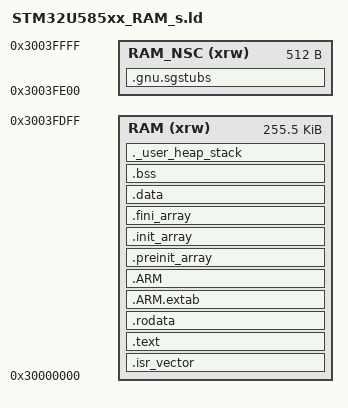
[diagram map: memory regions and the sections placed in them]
/*
******************************************************************************
**
**  File        : LinkerScript.ld (debug in RAM dedicated)
**
**  Author		: Auto-generated by STM32CubeIDE
**
**  Abstract    : Linker script for STM32U585xx Device from STM32U5 series
**                      768Kbytes RAM
**
**                Set heap size, stack size and stack location according
**                to application requirements.
**
**                Set memory bank area and size if external memory is used.
**
**  Target      : STMicroelectronics STM32
**
**  Distribution: The file is distributed as is without any warranty
**                of any kind.
**
*****************************************************************************
** @attention
**
** <h2><center>&copy; Copyright (c) 2021 STMicroelectronics.
** All rights reserved.</center></h2>
**
** This software component is licensed by ST under BSD 3-Clause license,
** the "License"; You may not use this file except in compliance with the
** License. You may obtain a copy of the License at:
**                        opensource.org/licenses/BSD-3-Clause
**
*****************************************************************************
*/

/* Entry Point */
ENTRY(Reset_Handler)

/* Highest address of the user mode stack */
_estack = ORIGIN(RAM) + LENGTH(RAM);	/* end of "RAM" Ram type memory */

_Min_Heap_Size = 0x200;	/* required amount of heap  */
_Min_Stack_Size = 0x400;	/* required amount of stack */

/* Memories definition */
MEMORY
{
  RAM	(xrw)	: ORIGIN = 0x30000000,	LENGTH = 256K - 512 /* Memory is divided. Actual start is 0x30000000 and actual length is 768K */
  RAM_NSC	(xrw)	: ORIGIN = 0x3003FE00,	LENGTH = 512    /* Non-Secure Call-able region */
}

/* Sections */
SECTIONS
{
  /* The startup code into "RAM" Ram type memory */
  .isr_vector :
  {
    . = ALIGN(8);
    KEEP(*(.isr_vector)) /* Startup code */
    . = ALIGN(8);
  } >RAM

  /* The program code and other data into "RAM" Ram type memory */
  .text :
  {
    . = ALIGN(8);
    *(.text)           /* .text sections (code) */
    *(.text*)          /* .text* sections (code) */
    *(.glue_7)         /* glue arm to thumb code */
    *(.glue_7t)        /* glue thumb to arm code */
    *(.eh_frame)

    KEEP (*(.init))
    KEEP (*(.fini))

    . = ALIGN(8);
    _etext = .;        /* define a global symbols at end of code */
  } >RAM

  /* Constant data into "RAM" Ram type memory */
  .rodata :
  {
    . = ALIGN(8);
    *(.rodata)         /* .rodata sections (constants, strings, etc.) */
    *(.rodata*)        /* .rodata* sections (constants, strings, etc.) */
    . = ALIGN(8);
  } >RAM

  .ARM.extab   : { 
    . = ALIGN(8);
    *(.ARM.extab* .gnu.linkonce.armextab.*)
    . = ALIGN(8);
  } >RAM
  
  .ARM : {
    . = ALIGN(8);
    __exidx_start = .;
    *(.ARM.exidx*)
    __exidx_end = .;
    . = ALIGN(8);
  } >RAM

  .preinit_array     :
  {
    . = ALIGN(8);
    PROVIDE_HIDDEN (__preinit_array_start = .);
    KEEP (*(.preinit_array*))
    PROVIDE_HIDDEN (__preinit_array_end = .);
    . = ALIGN(8);
  } >RAM
  
  .init_array :
  {
    . = ALIGN(8);
    PROVIDE_HIDDEN (__init_array_start = .);
    KEEP (*(SORT(.init_array.*)))
    KEEP (*(.init_array*))
    PROVIDE_HIDDEN (__init_array_end = .);
    . = ALIGN(8);
  } >RAM
  
  .fini_array :
  {
    . = ALIGN(8);
    PROVIDE_HIDDEN (__fini_array_start = .);
    KEEP (*(SORT(.fini_array.*)))
    KEEP (*(.fini_array*))
    PROVIDE_HIDDEN (__fini_array_end = .);
    . = ALIGN(8);
  } >RAM

  /* Used by the startup to initialize data */
  _sidata = LOADADDR(.data);

  /* Initialized data sections into "RAM" Ram type memory */
  .data : 
  {
    . = ALIGN(8);
    _sdata = .;        /* create a global symbol at data start */
    *(.data)           /* .data sections */
    *(.data*)          /* .data* sections */

    . = ALIGN(8);
    _edata = .;        /* define a global symbol at data end */
    
  } >RAM

  .gnu.sgstubs :
  {
    . = ALIGN(8);
    *(.gnu.sgstubs*)   /* Secure Gateway stubs */
    . = ALIGN(8);
  } >RAM_NSC

  /* Uninitialized data section into "RAM" Ram type memory */
  . = ALIGN(8);
  .bss :
  {
    /* This is used by the startup in order to initialize the .bss section */
    _sbss = .;         /* define a global symbol at bss start */
    __bss_start__ = _sbss;
    *(.bss)
    *(.bss*)
    *(COMMON)

    . = ALIGN(8);
    _ebss = .;         /* define a global symbol at bss end */
    __bss_end__ = _ebss;
  } >RAM

  /* User_heap_stack section, used to check that there is enough "RAM" Ram  type memory left */
  ._user_heap_stack :
  {
    . = ALIGN(8);
    PROVIDE ( end = . );
    PROVIDE ( _end = . );
    . = . + _Min_Heap_Size;
    . = . + _Min_Stack_Size;
    . = ALIGN(8);
  } >RAM

  /* Remove information from the compiler libraries */
  /DISCARD/ :
  {
    libc.a ( * )
    libm.a ( * )
    libgcc.a ( * )
  }

  .ARM.attributes 0 : { *(.ARM.attributes) }
}
